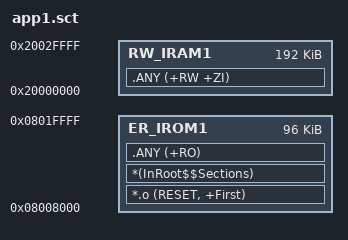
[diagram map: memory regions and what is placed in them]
; *************************************************************
; *** APP1 Scatter-Loading Description File ***
; *** STM32F407ZGTx, APP1 @ 0x08008000, size 96KB ***
; *************************************************************

LR_IROM1 0x08008000 0x00018000  {    ; 96KB APP1
  ER_IROM1 0x08008000 0x00018000  {  ; load address = execution address
    *.o (RESET, +First)
    *(InRoot$$Sections)
    .ANY (+RO)
  }

  RW_IRAM1 0x20000000 0x00030000  {  ; 192KB SRAM
    .ANY (+RW +ZI)
  }
}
